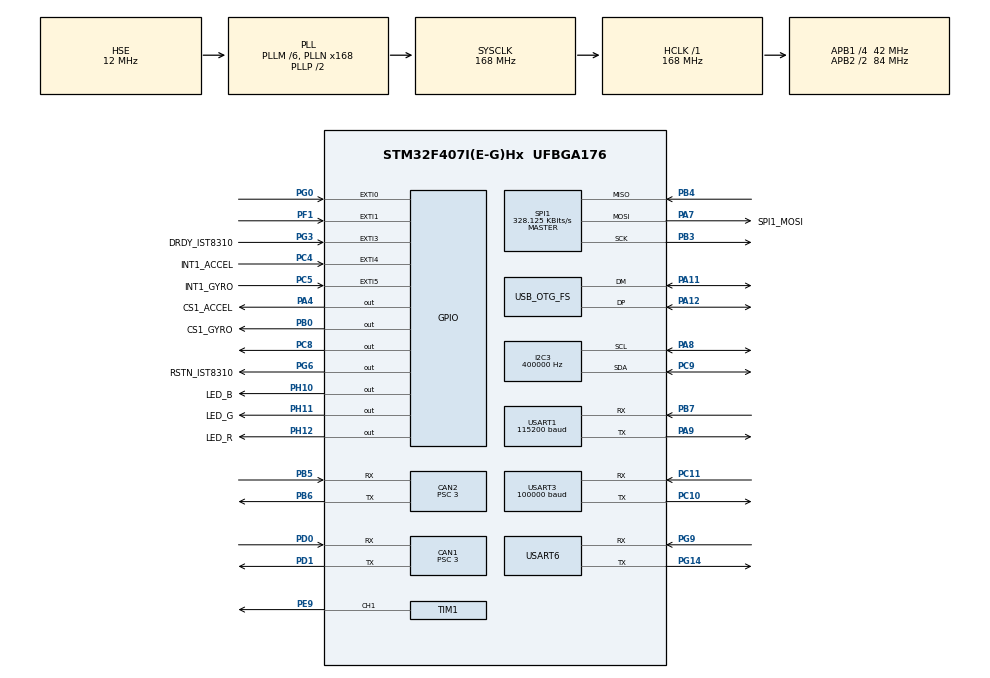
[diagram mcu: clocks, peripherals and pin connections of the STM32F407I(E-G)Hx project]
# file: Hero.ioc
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CAN1.ABOM=DISABLE
CAN1.AWUM=ENABLE
CAN1.BS1=CAN_BS1_10TQ
CAN1.BS2=CAN_BS2_3TQ
CAN1.CalculateBaudRate=1000000
CAN1.CalculateTimeBit=1000
CAN1.CalculateTimeQuantum=71.42857142857143
CAN1.Mode=CAN_MODE_NORMAL
CAN1.NART=ENABLE
CAN1.Prescaler=3
CAN1.RFLM=DISABLE
CAN1.SJW=CAN_SJW_1TQ
CAN1.TTCM=DISABLE
CAN1.TXFP=DISABLE
CAN2.ABOM=DISABLE
CAN2.AWUM=ENABLE
CAN2.BS1=CAN_BS1_10TQ
CAN2.BS2=CAN_BS2_3TQ
CAN2.CalculateBaudRate=1000000
CAN2.CalculateTimeBit=1000
CAN2.CalculateTimeQuantum=71.42857142857143
CAN2.Mode=CAN_MODE_NORMAL
CAN2.NART=ENABLE
CAN2.Prescaler=3
CAN2.RFLM=DISABLE
CAN2.SJW=CAN_SJW_1TQ
CAN2.TTCM=DISABLE
CAN2.TXFP=DISABLE
Dma.Request0=USART3_RX
Dma.Request1=SPI1_RX
Dma.Request2=SPI1_TX
Dma.Request3=USART1_RX
Dma.Request4=USART1_TX
Dma.Request5=USART6_RX
Dma.Request6=USART6_TX
Dma.SPI1_RX.1.Direction=DMA_PERIPH_TO_MEMORY
Dma.SPI1_RX.1.FIFOMode=DMA_FIFOMODE_DISABLE
Dma.SPI1_RX.1.Instance=DMA2_Stream2
Dma.SPI1_RX.1.MemDataAlignment=DMA_MDATAALIGN_BYTE
Dma.SPI1_RX.1.MemInc=DMA_MINC_ENABLE
Dma.SPI1_RX.1.Mode=DMA_NORMAL
Dma.SPI1_RX.1.PeriphDataAlignment=DMA_PDATAALIGN_BYTE
Dma.SPI1_RX.1.PeriphInc=DMA_PINC_DISABLE
Dma.SPI1_RX.1.Priority=DMA_PRIORITY_VERY_HIGH
Dma.SPI1_TX.2.Direction=DMA_MEMORY_TO_PERIPH
Dma.SPI1_TX.2.FIFOMode=DMA_FIFOMODE_DISABLE
Dma.SPI1_TX.2.Instance=DMA2_Stream3
Dma.SPI1_TX.2.MemDataAlignment=DMA_MDATAALIGN_BYTE
Dma.SPI1_TX.2.MemInc=DMA_MINC_ENABLE
Dma.SPI1_TX.2.Mode=DMA_NORMAL
Dma.SPI1_TX.2.PeriphDataAlignment=DMA_PDATAALIGN_BYTE
Dma.SPI1_TX.2.PeriphInc=DMA_PINC_DISABLE
Dma.SPI1_TX.2.Priority=DMA_PRIORITY_HIGH
Dma.USART1_RX.3.Direction=DMA_PERIPH_TO_MEMORY
Dma.USART1_RX.3.FIFOMode=DMA_FIFOMODE_DISABLE
Dma.USART1_RX.3.Instance=DMA2_Stream5
Dma.USART1_RX.3.MemDataAlignment=DMA_MDATAALIGN_BYTE
Dma.USART1_RX.3.MemInc=DMA_MINC_ENABLE
Dma.USART1_RX.3.Mode=DMA_NORMAL
Dma.USART1_RX.3.PeriphDataAlignment=DMA_PDATAALIGN_BYTE
Dma.USART1_RX.3.PeriphInc=DMA_PINC_DISABLE
Dma.USART1_RX.3.Priority=DMA_PRIORITY_LOW
Dma.USART1_TX.4.Direction=DMA_MEMORY_TO_PERIPH
Dma.USART1_TX.4.FIFOMode=DMA_FIFOMODE_DISABLE
Dma.USART1_TX.4.Instance=DMA2_Stream7
Dma.USART1_TX.4.MemDataAlignment=DMA_MDATAALIGN_BYTE
Dma.USART1_TX.4.MemInc=DMA_MINC_ENABLE
Dma.USART1_TX.4.Mode=DMA_CIRCULAR
Dma.USART1_TX.4.PeriphDataAlignment=DMA_PDATAALIGN_BYTE
Dma.USART1_TX.4.PeriphInc=DMA_PINC_DISABLE
Dma.USART1_TX.4.Priority=DMA_PRIORITY_LOW
Dma.USART3_RX.0.Direction=DMA_PERIPH_TO_MEMORY
Dma.USART3_RX.0.FIFOMode=DMA_FIFOMODE_DISABLE
Dma.USART3_RX.0.Instance=DMA1_Stream1
Dma.USART3_RX.0.MemDataAlignment=DMA_MDATAALIGN_BYTE
Dma.USART3_RX.0.MemInc=DMA_MINC_ENABLE
Dma.USART3_RX.0.Mode=DMA_CIRCULAR
Dma.USART3_RX.0.PeriphDataAlignment=DMA_PDATAALIGN_BYTE
Dma.USART3_RX.0.PeriphInc=DMA_PINC_DISABLE
Dma.USART3_RX.0.Priority=DMA_PRIORITY_VERY_HIGH
Dma.USART6_RX.5.Direction=DMA_PERIPH_TO_MEMORY
Dma.USART6_RX.5.FIFOMode=DMA_FIFOMODE_DISABLE
Dma.USART6_RX.5.Instance=DMA2_Stream1
Dma.USART6_RX.5.MemDataAlignment=DMA_MDATAALIGN_BYTE
Dma.USART6_RX.5.MemInc=DMA_MINC_ENABLE
Dma.USART6_RX.5.Mode=DMA_NORMAL
Dma.USART6_RX.5.PeriphDataAlignment=DMA_PDATAALIGN_BYTE
Dma.USART6_RX.5.PeriphInc=DMA_PINC_DISABLE
Dma.USART6_RX.5.Priority=DMA_PRIORITY_HIGH
Dma.USART6_TX.6.Direction=DMA_MEMORY_TO_PERIPH
Dma.USART6_TX.6.FIFOMode=DMA_FIFOMODE_DISABLE
Dma.USART6_TX.6.Instance=DMA2_Stream6
Dma.USART6_TX.6.MemDataAlignment=DMA_MDATAALIGN_BYTE
Dma.USART6_TX.6.MemInc=DMA_MINC_ENABLE
Dma.USART6_TX.6.Mode=DMA_NORMAL
Dma.USART6_TX.6.PeriphDataAlignment=DMA_PDATAALIGN_BYTE
Dma.USART6_TX.6.PeriphInc=DMA_PINC_DISABLE
Dma.USART6_TX.6.Priority=DMA_PRIORITY_MEDIUM
FREERTOS.HEAP_NUMBER=4
FREERTOS.INCLUDE_eTaskGetState=0
FREERTOS.INCLUDE_pcTaskGetTaskName=0
FREERTOS.INCLUDE_uxTaskGetStackHighWaterMark=0
FREERTOS.INCLUDE_uxTaskGetStackHighWaterMark2=0
FREERTOS.INCLUDE_uxTaskPriorityGet=1
FREERTOS.INCLUDE_vTaskCleanUpResources=0
FREERTOS.INCLUDE_vTaskDelay=1
FREERTOS.INCLUDE_vTaskDelayUntil=1
FREERTOS.INCLUDE_vTaskDelete=1
FREERTOS.INCLUDE_vTaskPrioritySet=1
FREERTOS.INCLUDE_vTaskSuspend=1
FREERTOS.INCLUDE_xEventGroupSetBitFromISR=0
FREERTOS.INCLUDE_xQueueGetMutexHolder=0
FREERTOS.INCLUDE_xSemaphoreGetMutexHolder=0
FREERTOS.INCLUDE_xTaskAbortDelay=0
FREERTOS.INCLUDE_xTaskGetCurrentTaskHandle=0
FREERTOS.INCLUDE_xTaskGetHandle=1
FREERTOS.INCLUDE_xTaskResumeFromISR=1
FREERTOS.MEMORY_ALLOCATION=2
FREERTOS.Tasks01=defaultTask,0,128,StartDefaultTask,Default,NULL,Dynamic,NULL,NULL;CHASSIS_TASK,2,256,Chassis_task,As weak,NULL,Dynamic,NULL,NULL
FREERTOS.configCHECK_FOR_STACK_OVERFLOW=0
FREERTOS.configENABLE_BACKWARD_COMPATIBILITY=1
FREERTOS.configENABLE_FPU=0
FREERTOS.configGENERATE_RUN_TIME_STATS=0
FREERTOS.configIDLE_SHOULD_YIELD=1
FREERTOS.configLIBRARY_LOWEST_INTERRUPT_PRIORITY=15
FREERTOS.configLIBRARY_MAX_SYSCALL_INTERRUPT_PRIORITY=5
FREERTOS.configMAX_CO_ROUTINE_PRIORITIES=2
FREERTOS.configMAX_PRIORITIES=7
FREERTOS.configMAX_TASK_NAME_LEN=16
FREERTOS.configMINIMAL_STACK_SIZE=128
FREERTOS.configQUEUE_REGISTRY_SIZE=8
FREERTOS.configRECORD_STACK_HIGH_ADDRESS=0
FREERTOS.configTICK_RATE_HZ=1000
FREERTOS.configTOTAL_HEAP_SIZE=15360
FREERTOS.configUSE_APPLICATION_TASK_TAG=0
FREERTOS.configUSE_COUNTING_SEMAPHORES=0
FREERTOS.configUSE_CO_ROUTINES=0
FREERTOS.configUSE_DAEMON_TASK_STARTUP_HOOK=0
FREERTOS.configUSE_IDLE_HOOK=0
FREERTOS.configUSE_MALLOC_FAILED_HOOK=0
FREERTOS.configUSE_MUTEXES=1
FREERTOS.configUSE_NEWLIB_REENTRANT=0
FREERTOS.configUSE_POSIX_ERRNO=0
FREERTOS.configUSE_PREEMPTION=1
FREERTOS.configUSE_RECURSIVE_MUTEXES=0
FREERTOS.configUSE_STATS_FORMATTING_FUNCTIONS=0
FREERTOS.configUSE_TASK_NOTIFICATIONS=1
FREERTOS.configUSE_TICKLESS_IDLE=0
FREERTOS.configUSE_TICK_HOOK=0
FREERTOS.configUSE_TIMERS=0
FREERTOS.configUSE_TRACE_FACILITY=0
FREERTOS.copyHeapFile=1
I2C3.AddressingMode=I2C_ADDRESSINGMODE_7BIT
I2C3.ClockSpeed=400000
I2C3.DualAddressMode=I2C_DUALADDRESS_DISABLE
I2C3.DutyCycle=I2C_DUTYCYCLE_2
I2C3.GeneralCallMode=I2C_GENERALCALL_DISABLE
I2C3.I2C_Mode=I2C_Fast
I2C3.NoStretchMode=I2C_NOSTRETCH_DISABLE
I2C3.OwnAddress=0
Mcu.Family=STM32F4
Mcu.Name=STM32F407I(E-G)Hx
Mcu.Package=UFBGA176
NVIC.CAN1_RX0_IRQn=true\:5\:0\:true\:false\:true\:true\:true\:true\:true
NVIC.CAN2_RX1_IRQn=true\:5\:0\:false\:false\:true\:true\:true\:true\:true
NVIC.DMA1_Stream1_IRQn=true\:5\:0\:true\:false\:true\:true\:false\:true\:true
NVIC.DMA2_Stream1_IRQn=true\:5\:0\:false\:false\:true\:true\:false\:true\:true
NVIC.DMA2_Stream2_IRQn=true\:5\:0\:true\:false\:true\:true\:false\:true\:true
NVIC.DMA2_Stream3_IRQn=true\:5\:0\:false\:false\:true\:true\:false\:true\:true
NVIC.DMA2_Stream5_IRQn=true\:5\:0\:false\:false\:true\:true\:false\:true\:true
NVIC.DMA2_Stream6_IRQn=true\:5\:0\:false\:false\:true\:true\:false\:true\:true
NVIC.DMA2_Stream7_IRQn=true\:5\:0\:false\:false\:true\:true\:false\:true\:true
NVIC.EXTI0_IRQn=true\:6\:0\:true\:false\:true\:true\:true\:true\:true
NVIC.EXTI1_IRQn=true\:5\:0\:true\:false\:true\:true\:true\:true\:true
NVIC.EXTI3_IRQn=true\:5\:0\:true\:false\:true\:true\:true\:true\:true
NVIC.EXTI4_IRQn=true\:5\:0\:true\:false\:true\:true\:true\:true\:true
NVIC.EXTI9_5_IRQn=true\:5\:0\:true\:false\:true\:true\:true\:true\:true
NVIC.OTG_FS_IRQn=true\:5\:0\:false\:false\:true\:true\:true\:true\:true
NVIC.PriorityGroup=NVIC_PRIORITYGROUP_4
NVIC.TIM1_UP_TIM10_IRQn=true\:5\:0\:false\:false\:true\:true\:true\:true\:true
NVIC.TIM4_IRQn=true\:5\:0\:false\:false\:true\:true\:true\:true\:true
NVIC.TIM6_DAC_IRQn=true\:15\:0\:false\:false\:true\:false\:false\:true\:true
NVIC.TIM8_UP_TIM13_IRQn=true\:5\:0\:false\:false\:true\:true\:true\:true\:true
NVIC.TimeBase=TIM6_DAC_IRQn
NVIC.TimeBaseIP=TIM6
NVIC.USART1_IRQn=true\:5\:0\:false\:false\:true\:true\:true\:true\:true
NVIC.USART3_IRQn=true\:5\:0\:true\:false\:true\:true\:true\:true\:true
NVIC.USART6_IRQn=true\:5\:0\:false\:false\:true\:true\:true\:true\:true
PA11.Mode=Device_Only
PA11.Signal=USB_OTG_FS_DM
PA12.Mode=Device_Only
PA12.Signal=USB_OTG_FS_DP
PA13.Mode=Serial_Wire
PA13.Signal=SYS_JTMS-SWDIO
PA14.Mode=Serial_Wire
PA14.Signal=SYS_JTCK-SWCLK
PA4.GPIO_Label=CS1_ACCEL
PA4.PinState=GPIO_PIN_SET
PA4.Signal=GPIO_Output
PA7.GPIO_Label=SPI1_MOSI
PA7.GPIO_PuPd=GPIO_PULLUP
PA7.Mode=Full_Duplex_Master
PA7.Signal=SPI1_MOSI
PA8.Mode=I2C
PA8.Signal=I2C3_SCL
PA9.Mode=Asynchronous
PA9.Signal=USART1_TX
PB0.GPIO_Label=CS1_GYRO
PB0.PinState=GPIO_PIN_SET
PB0.Signal=GPIO_Output
PB3.Mode=Full_Duplex_Master
PB3.Signal=SPI1_SCK
PB4.GPIO_PuPd=GPIO_PULLUP
PB4.Mode=Full_Duplex_Master
PB4.Signal=SPI1_MISO
PB5.Mode=CAN_Activate
PB5.Signal=CAN2_RX
PB6.Mode=CAN_Activate
PB6.Signal=CAN2_TX
PB7.Mode=Asynchronous
PB7.Signal=USART1_RX
PC10.Mode=Asynchronous
PC10.Signal=USART3_TX
PC11.Mode=Asynchronous
PC11.Signal=USART3_RX
PC4.GPIO_Label=INT1_ACCEL
PC4.GPIO_PuPd=GPIO_PULLUP
PC4.Signal=GPXTI4
PC5.GPIO_Label=INT1_GYRO
PC5.GPIO_PuPd=GPIO_PULLUP
PC5.Signal=GPXTI5
PC8.GPIO_PuPd=GPIO_PULLUP
PC8.Signal=GPIO_Output
PC9.Mode=I2C
PC9.Signal=I2C3_SDA
PD0.Mode=CAN_Activate
PD0.Signal=CAN1_RX
PD1.Mode=CAN_Activate
PD1.Signal=CAN1_TX
PE9.Signal=S_TIM1_CH1
PF1.Signal=GPXTI1
PF6.Signal=S_TIM10_CH1
PG0.GPIO_PuPd=GPIO_PULLUP
PG0.Signal=GPXTI0
PG14.Mode=Asynchronous
PG14.Signal=USART6_TX
PG3.GPIO_Label=DRDY_IST8310
PG3.GPIO_PuPd=GPIO_PULLUP
PG3.Signal=GPXTI3
PG6.GPIO_Label=RSTN_IST8310
PG6.GPIO_PuPd=GPIO_PULLUP
PG6.GPIO_Speed=GPIO_SPEED_FREQ_MEDIUM
PG6.PinState=GPIO_PIN_SET
PG6.Signal=GPIO_Output
PG9.Mode=Asynchronous
PG9.Signal=USART6_RX
PH0-OSC_IN.Mode=HSE-External-Oscillator
PH0-OSC_IN.Signal=RCC_OSC_IN
PH1-OSC_OUT.Mode=HSE-External-Oscillator
PH1-OSC_OUT.Signal=RCC_OSC_OUT
PH10.GPIO_Label=LED_B
PH10.Signal=GPIO_Output
PH11.GPIO_Label=LED_G
PH11.Signal=GPIO_Output
PH12.GPIO_Label=LED_R
PH12.Signal=GPIO_Output
ProjectManager.HeapSize=0x200
ProjectManager.StackSize=0x400
ProjectManager.TargetToolchain=MDK-ARM V5.32
RCC.48MHZClocksFreq_Value=48000000
RCC.AHBFreq_Value=168000000
RCC.APB1CLKDivider=RCC_HCLK_DIV4
RCC.APB1Freq_Value=42000000
RCC.APB1TimFreq_Value=84000000
RCC.APB2CLKDivider=RCC_HCLK_DIV2
RCC.APB2Freq_Value=84000000
RCC.APB2TimFreq_Value=168000000
RCC.CortexFreq_Value=168000000
RCC.FLatency=FLASH_LATENCY_5
RCC.HCLKFreq_Value=168000000
RCC.HSE_VALUE=12000000
RCC.HSI_VALUE=16000000
RCC.LSE_VALUE=32768
RCC.PLLM=6
RCC.PLLN=168
RCC.PLLQ=7
RCC.SYSCLKFreq_VALUE=168000000
RCC.SYSCLKSource=RCC_SYSCLKSOURCE_PLLCLK
RCC.VCOOutputFreq_Value=336000000
SH.S_TIM10_CH1.0=TIM10_CH1
SH.S_TIM1_CH1.0=TIM1_CH1,PWM Generation1 CH1
SPI1.BaudRatePrescaler=SPI_BAUDRATEPRESCALER_256
SPI1.CLKPhase=SPI_PHASE_2EDGE
SPI1.CLKPolarity=SPI_POLARITY_HIGH
SPI1.CRCCalculation=SPI_CRCCALCULATION_DISABLE
SPI1.CalculateBaudRate=328.125 KBits/s
SPI1.DataSize=SPI_DATASIZE_8BIT
SPI1.Direction=SPI_DIRECTION_2LINES
SPI1.FirstBit=SPI_FIRSTBIT_MSB
SPI1.Mode=SPI_MODE_MASTER
SPI1.NSS=SPI_NSS_SOFT
SPI1.TIMode=SPI_TIMODE_DISABLE
SPI1.VirtualType=VM_MASTER
TIM1.AutoReloadPreload=TIM_AUTORELOAD_PRELOAD_ENABLE
TIM1.AutomaticOutput=TIM_AUTOMATICOUTPUT_DISABLE
TIM1.BreakPolarity=TIM_BREAKPOLARITY_HIGH
TIM1.BreakState=TIM_BREAK_DISABLE
TIM1.Channel-PWM\ Generation1\ CH1=TIM_CHANNEL_1
TIM1.ClockDivision=TIM_CLOCKDIVISION_DIV1
TIM1.CounterMode=TIM_COUNTERMODE_UP
TIM1.LockLevel=TIM_LOCKLEVEL_OFF
TIM1.OC1Preload_PWM=ENABLE
TIM1.OCFastMode_PWM-PWM\ Generation1\ CH1=TIM_OCFAST_DISABLE
TIM1.OCIdleState_1=TIM_OCIDLESTATE_RESET
TIM1.OCMode_PWM-PWM\ Generation1\ CH1=TIM_OCMODE_PWM1
TIM1.OCPolarity_1=TIM_OCPOLARITY_HIGH
TIM1.OffStateIDLEMode=TIM_OSSI_DISABLE
TIM1.OffStateRunMode=TIM_OSSR_DISABLE
TIM1.Period=499
TIM1.Prescaler=335
TIM1.Pulse-PWM\ Generation1\ CH1=0
TIM1.RepetitionCounter=0
TIM1.TIM_MasterOutputTrigger=TIM_TRGO_RESET
TIM1.TIM_MasterSlaveMode=TIM_MASTERSLAVEMODE_DISABLE
TIM10.AutoReloadPreload=TIM_AUTORELOAD_PRELOAD_DISABLE
TIM10.Channel=TIM_CHANNEL_1
TIM10.ClockDivision=TIM_CLOCKDIVISION_DIV1
TIM10.CounterMode=TIM_COUNTERMODE_UP
TIM10.OC1Preload_PWM=ENABLE
TIM10.OCFastMode_PWM=TIM_OCFAST_DISABLE
TIM10.OCMode_PWM=TIM_OCMODE_PWM1
TIM10.OCPolarity_1=TIM_OCPOLARITY_HIGH
TIM10.Period=4999
TIM10.Prescaler=0
TIM10.Pulse=0
TIM13.AutoReloadPreload=TIM_AUTORELOAD_PRELOAD_DISABLE
TIM13.ClockDivision=TIM_CLOCKDIVISION_DIV1
TIM13.CounterMode=TIM_COUNTERMODE_UP
TIM13.Period=10000-1
TIM13.Prescaler=8400-1
TIM4.Period=4999
TIM4.Prescaler=16799
USART1.BaudRate=115200
USART1.Mode=MODE_TX_RX
USART1.OverSampling=UART_OVERSAMPLING_16
USART1.Parity=PARITY_NONE
USART1.StopBits=STOPBITS_1
USART1.VirtualMode=VM_ASYNC
USART1.WordLength=WORDLENGTH_8B
USART3.BaudRate=100000
USART3.Mode=MODE_TX_RX
USART3.OverSampling=UART_OVERSAMPLING_16
USART3.Parity=PARITY_EVEN
USART3.StopBits=STOPBITS_1
USART3.VirtualMode=VM_ASYNC
USART3.WordLength=WORDLENGTH_8B
USART6.VirtualMode=VM_ASYNC
USB_OTG_FS.Sof_enable=DISABLE
USB_OTG_FS.VirtualMode=Device_Only
USB_OTG_FS.low_power_enable=DISABLE
USB_OTG_FS.lpm_enable=DISABLE
USB_OTG_FS.vbus_sensing_enable=DISABLE
VP_CRC_VS_CRC.Mode=CRC_Activate
VP_FREERTOS_VS_CMSIS_V1.Mode=CMSIS_V1
VP_SYS_VS_tim6.Mode=TIM6
VP_TIM10_VS_ClockSourceINT.Mode=Enable_Timer
VP_TIM13_VS_ClockSourceINT.Mode=Enable_Timer
VP_TIM1_VS_ClockSourceINT.Mode=Internal
VP_TIM4_VS_ClockSourceINT.Mode=Internal
board=custom

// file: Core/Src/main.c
/* USER CODE BEGIN Header */
/**
  ******************************************************************************
  * @file           : main.c
  * @brief          : Main program body
  ******************************************************************************
  * @attention
  *
  * Copyright (c) 2025 STMicroelectronics.
  * All rights reserved.
  *
  * This software is licensed under terms that can be found in the LICENSE file
  * in the root directory of this software component.
  * If no LICENSE file comes with this software, it is provided AS-IS.
  *
  ******************************************************************************
  */
/* USER CODE END Header */
#include "main.h"
#include "cmsis_os.h"
#include "can.h"
#include "crc.h"
#include "dma.h"
#include "i2c.h"
#include "spi.h"
#include "tim.h"
#include "usart.h"
#include "usb_otg.h"
#include "gpio.h"

/* USER CODE BEGIN Includes */
#include "bsp_can.h"
#include "bsp_uart.h"
#include "dev_remote_control.h"
#include "bsp_log.h"
/* USER CODE END Includes */

void SystemClock_Config(void);
void MX_FREERTOS_Init(void);

int main(void)
{

  /* MCU Configuration--------------------------------------------------------*/

  /* Reset of all peripherals, Initializes the Flash interface and the Systick. */
  HAL_Init();

  /* Configure the system clock */
  SystemClock_Config();

  /* Initialize all configured peripherals */
  MX_GPIO_Init();
  MX_DMA_Init();
  MX_CAN1_Init();
  MX_USART3_UART_Init();
  MX_SPI1_Init();
  MX_TIM10_Init();
  MX_I2C3_Init();
  MX_CAN2_Init();
  MX_USART1_UART_Init();
  MX_TIM1_Init();
  MX_CRC_Init();
  MX_TIM13_Init();
  MX_USB_OTG_FS_PCD_Init();
  MX_TIM4_Init();
  MX_USART6_UART_Init();
  /* USER CODE BEGIN 2 */
//	Can_Init();
  /* USER CODE END 2 */

  /* Call init function for freertos objects (in cmsis_os2.c) */
  MX_FREERTOS_Init();

  /* Start scheduler */
  osKernelStart();

  /* We should never get here as control is now taken by the scheduler */

  /* Infinite loop */
  while (1)
  {

  }
}

void SystemClock_Config(void)
{
  RCC_OscInitTypeDef RCC_OscInitStruct = {0};
  RCC_ClkInitTypeDef RCC_ClkInitStruct = {0};

  /** Configure the main internal regulator output voltage
  */
  __HAL_RCC_PWR_CLK_ENABLE();
  __HAL_PWR_VOLTAGESCALING_CONFIG(PWR_REGULATOR_VOLTAGE_SCALE1);

  /** Initializes the RCC Oscillators according to the specified parameters
  * in the RCC_OscInitTypeDef structure.
  */
  RCC_OscInitStruct.OscillatorType = RCC_OSCILLATORTYPE_HSE;
  RCC_OscInitStruct.HSEState = RCC_HSE_ON;
  RCC_OscInitStruct.PLL.PLLState = RCC_PLL_ON;
  RCC_OscInitStruct.PLL.PLLSource = RCC_PLLSOURCE_HSE;
  RCC_OscInitStruct.PLL.PLLM = 6;
  RCC_OscInitStruct.PLL.PLLN = 168;
  RCC_OscInitStruct.PLL.PLLP = RCC_PLLP_DIV2;
  RCC_OscInitStruct.PLL.PLLQ = 7;
  if (HAL_RCC_OscConfig(&RCC_OscInitStruct) != HAL_OK)
  {
    Error_Handler();
  }

  /** Initializes the CPU, AHB and APB buses clocks
  */
  RCC_ClkInitStruct.ClockType = RCC_CLOCKTYPE_HCLK|RCC_CLOCKTYPE_SYSCLK
                              |RCC_CLOCKTYPE_PCLK1|RCC_CLOCKTYPE_PCLK2;
  RCC_ClkInitStruct.SYSCLKSource = RCC_SYSCLKSOURCE_PLLCLK;
  RCC_ClkInitStruct.AHBCLKDivider = RCC_SYSCLK_DIV1;
  RCC_ClkInitStruct.APB1CLKDivider = RCC_HCLK_DIV4;
  RCC_ClkInitStruct.APB2CLKDivider = RCC_HCLK_DIV2;

  if (HAL_RCC_ClockConfig(&RCC_ClkInitStruct, FLASH_LATENCY_5) != HAL_OK)
  {
    Error_Handler();
  }
}

void HAL_TIM_PeriodElapsedCallback(TIM_HandleTypeDef *htim)
{
  if (htim->Instance == TIM6)
  {
    HAL_IncTick();
  }
}

void Error_Handler(void)
{
  __disable_irq();
  while (1)
  {
  }
}

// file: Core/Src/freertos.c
/* USER CODE BEGIN Header */
/**
  ******************************************************************************
  * File Name          : freertos.c
  * Description        : Code for freertos applications
  ******************************************************************************
  * @attention
  *
  * Copyright (c) 2025 STMicroelectronics.
  * All rights reserved.
  *
  * This software is licensed under terms that can be found in the LICENSE file
  * in the root directory of this software component.
  * If no LICENSE file comes with this software, it is provided AS-IS.
  *
  ******************************************************************************
  */
/* USER CODE END Header */

#include "FreeRTOS.h"
#include "task.h"
#include "main.h"
#include "cmsis_os.h"

osThreadId defaultTaskHandle;
osThreadId CHASSIS_TASKHandle;

void StartDefaultTask(void const * argument);
void Chassis_task(void const * argument);

void MX_FREERTOS_Init(void); /* (MISRA C 2004 rule 8.1) */

/* GetIdleTaskMemory prototype (linked to static allocation support) */
void vApplicationGetIdleTaskMemory( StaticTask_t **ppxIdleTaskTCBBuffer, StackType_t **ppxIdleTaskStackBuffer, uint32_t *pulIdleTaskStackSize );

/* USER CODE BEGIN GET_IDLE_TASK_MEMORY */
static StaticTask_t xIdleTaskTCBBuffer;
static StackType_t xIdleStack[configMINIMAL_STACK_SIZE];

void vApplicationGetIdleTaskMemory( StaticTask_t **ppxIdleTaskTCBBuffer, StackType_t **ppxIdleTaskStackBuffer, uint32_t *pulIdleTaskStackSize )
{
  *ppxIdleTaskTCBBuffer = &xIdleTaskTCBBuffer;
  *ppxIdleTaskStackBuffer = &xIdleStack[0];
  *pulIdleTaskStackSize = configMINIMAL_STACK_SIZE;
  /* place for user code */
}
/* USER CODE END GET_IDLE_TASK_MEMORY */

void MX_FREERTOS_Init(void) {

  /* Create the thread(s) */
  /* definition and creation of defaultTask */
  osThreadDef(defaultTask, StartDefaultTask, osPriorityNormal, 0, 128);
  defaultTaskHandle = osThreadCreate(osThread(defaultTask), NULL);

  /* definition and creation of CHASSIS_TASK */
  osThreadDef(CHASSIS_TASK, Chassis_task, osPriorityHigh, 0, 256);
  CHASSIS_TASKHandle = osThreadCreate(osThread(CHASSIS_TASK), NULL);

}

void StartDefaultTask(void const * argument)
{
  for(;;)
  {
    osDelay(1);
  }
}

__weak void Chassis_task(void const * argument)
{
  for(;;)
  {
    osDelay(1);
  }
}
